# ESP32-C6 register map
Vendor: ESPRESSIF SYSTEMS (SHANGHAI) CO., LTD.; Series: ESP32 C-Series; File version: 12
CPU: RV32IMAC r0p0, little endian, no MPU, no FPU, 0 interrupt priority bits
Address unit: 32 bits
Registers are 32-bit, read-write, reset 0x0 unless marked. A register's access mark holds for its fields unless they carry their own. Offsets are from the block's base; [hi:lo] are bit positions; {n}, {i} and the like mark numbered series.

## LP_TEE — Low-power Trusted Execution Environment
Base 0x600B3400
{0x0+4i} M{i}_MODE_CTRL (i=0..0) reset 0x3 — Tee mode control register
  [1:0] MODE — M0 security level mode: 2'd3: ree_mode2. 2'd2: ree_mode1. 2'd1: ree_mode0. 2'd0: tee_mode
    0=Tee (Tee mode); 1=Ree0 mode; 2=Ree1 mode; 3=Ree2 mode
0x04 CLOCK_GATE reset 0x1 — Clock gating register
  [0] CLK_EN — reg_clk_en
0x90 FORCE_ACC_HP — need_des
  [0] LP_AON_FORCE_ACC_HPMEM_EN
0xFC DATE — Version register

## LP_TIMER — Low-power Timer
Base 0x600B0C00
0x00 TAR0_LOW — need_des
  [31:0] MAIN_TIMER_TAR_LOW0
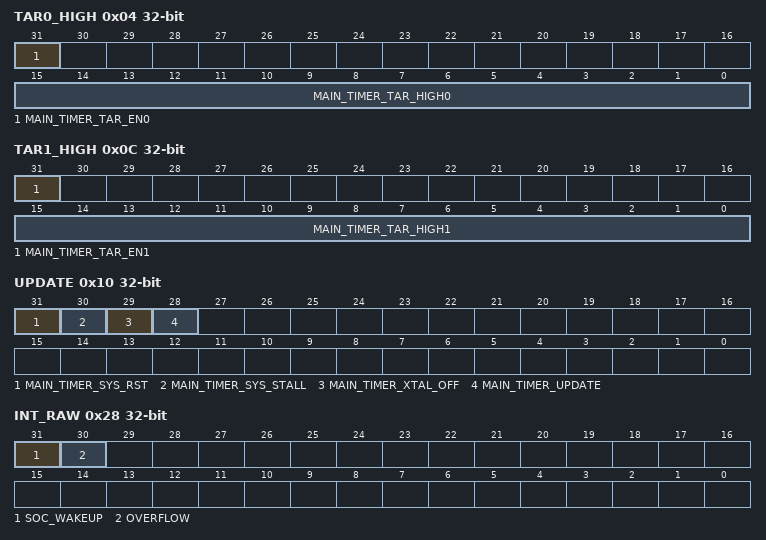
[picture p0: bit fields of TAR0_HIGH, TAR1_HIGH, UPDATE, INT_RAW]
0x04 TAR0_HIGH access per field — need_des
  [31] MAIN_TIMER_TAR_EN0 wo — need_des
  [15:0] MAIN_TIMER_TAR_HIGH0 rw — need_des
0x08 TAR1_LOW — need_des
  [31:0] MAIN_TIMER_TAR_LOW1
0x0C TAR1_HIGH access per field — need_des
  [31] MAIN_TIMER_TAR_EN1 wo — need_des
  [15:0] MAIN_TIMER_TAR_HIGH1 rw — need_des
0x10 UPDATE access per field — need_des
  [31] MAIN_TIMER_SYS_RST rw — need_des
  [30] MAIN_TIMER_SYS_STALL rw — need_des
  [29] MAIN_TIMER_XTAL_OFF rw — need_des
  [28] MAIN_TIMER_UPDATE wo — need_des
0x14 MAIN_BUF0_LOW ro — need_des
  [31:0] MAIN_TIMER_BUF0_LOW
0x18 MAIN_BUF0_HIGH ro — need_des
  [15:0] MAIN_TIMER_BUF0_HIGH
0x1C MAIN_BUF1_LOW ro — need_des
  [31:0] MAIN_TIMER_BUF1_LOW
0x20 MAIN_BUF1_HIGH ro — need_des
  [15:0] MAIN_TIMER_BUF1_HIGH
0x24 MAIN_OVERFLOW wo — need_des
  [31] MAIN_TIMER_ALARM_LOAD
0x28 INT_RAW — need_des
  [31] SOC_WAKEUP — need_des
  [30] OVERFLOW — need_des
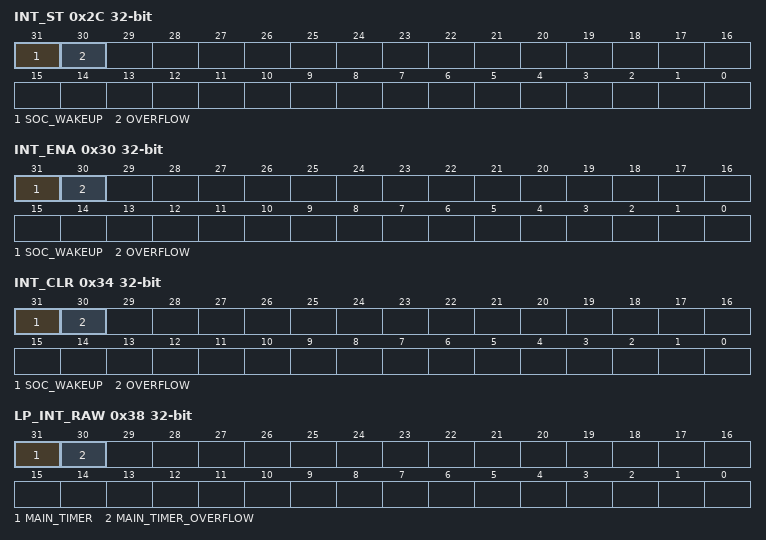
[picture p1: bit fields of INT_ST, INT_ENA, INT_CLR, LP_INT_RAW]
0x2C INT_ST ro — need_des
  [31] SOC_WAKEUP — need_des
  [30] OVERFLOW — need_des
0x30 INT_ENA — need_des
  [31] SOC_WAKEUP — need_des
  [30] OVERFLOW — need_des
0x34 INT_CLR wo — need_des
  [31] SOC_WAKEUP write-1-clears — need_des
  [30] OVERFLOW write-1-clears — need_des
0x38 LP_INT_RAW — need_des
  [31] MAIN_TIMER — need_des
  [30] MAIN_TIMER_OVERFLOW — need_des
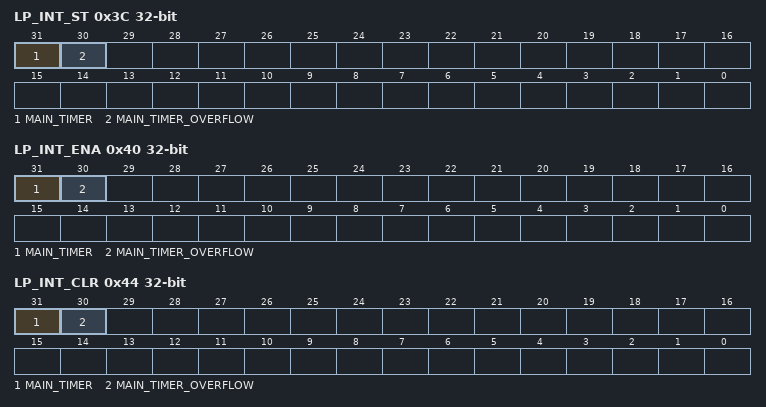
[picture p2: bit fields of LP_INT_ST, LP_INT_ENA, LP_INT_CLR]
0x3C LP_INT_ST ro — need_des
  [31] MAIN_TIMER — need_des
  [30] MAIN_TIMER_OVERFLOW — need_des
0x40 LP_INT_ENA — need_des
  [31] MAIN_TIMER — need_des
  [30] MAIN_TIMER_OVERFLOW — need_des
0x44 LP_INT_CLR wo — need_des
  [31] MAIN_TIMER write-1-clears — need_des
  [30] MAIN_TIMER_OVERFLOW write-1-clears — need_des
0x3FC DATE — need_des

## LP_WDT — Low-power Watchdog Timer
Base 0x600B1C00
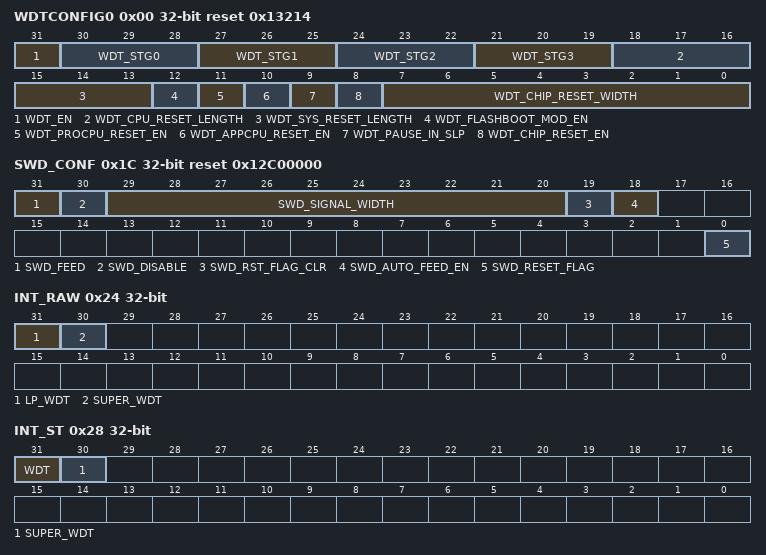
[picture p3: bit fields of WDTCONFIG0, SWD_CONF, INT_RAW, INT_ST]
0x00 WDTCONFIG0 reset 0x13214 — need_des
  [31] WDT_EN — need_des
  [30-3n:28-3n] WDT_STG{n} (n=0..3) — need_des
  [18:16] WDT_CPU_RESET_LENGTH — need_des
  [15:13] WDT_SYS_RESET_LENGTH — need_des
  [12] WDT_FLASHBOOT_MOD_EN — need_des
  [11] WDT_PROCPU_RESET_EN — need_des
  [10] WDT_APPCPU_RESET_EN — need_des
  [9] WDT_PAUSE_IN_SLP — need_des
  [8] WDT_CHIP_RESET_EN — need_des
  [7:0] WDT_CHIP_RESET_WIDTH — need_des
{0x0+4i} WDTCONFIG{i} (i=1..4) reset 0x30D40 — need_des
  [31:0] HOLD
0x14 WDTFEED wo — need_des
  [31] WDT_FEED
0x18 WDTWPROTECT — need_des
  [31:0] WDT_WKEY
0x1C SWD_CONF access per field reset 0x12C00000 — need_des
  [31] SWD_FEED wo — need_des
  [30] SWD_DISABLE rw — need_des
  [29:20] SWD_SIGNAL_WIDTH rw — need_des
  [19] SWD_RST_FLAG_CLR wo — need_des
  [18] SWD_AUTO_FEED_EN rw — need_des
  [0] SWD_RESET_FLAG ro — need_des
0x20 SWD_WPROTECT — need_des
  [31:0] SWD_WKEY
0x24 INT_RAW — need_des
  [31] LP_WDT — need_des
  [30] SUPER_WDT — need_des
0x28 INT_ST ro — need_des
  [31] WDT — need_des
  [30] SUPER_WDT — need_des
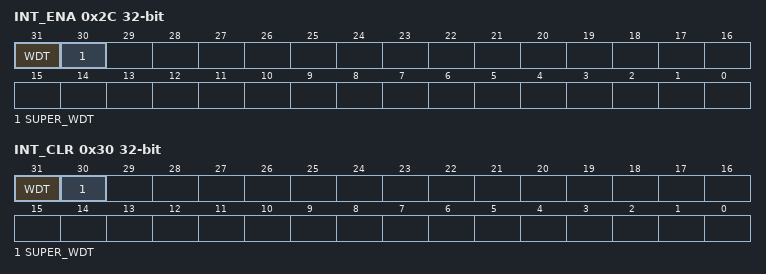
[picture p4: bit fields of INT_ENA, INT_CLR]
0x2C INT_ENA — need_des
  [31] WDT — need_des
  [30] SUPER_WDT — need_des
0x30 INT_CLR wo — need_des
  [31] WDT write-1-clears — need_des
  [30] SUPER_WDT write-1-clears — need_des
0x3FC DATE — need_des

## MEM_MONITOR — MEM_MONITOR Peripheral
Base 0x60092000
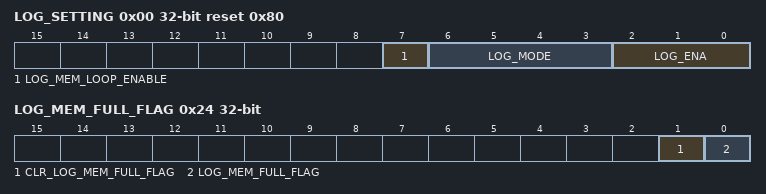
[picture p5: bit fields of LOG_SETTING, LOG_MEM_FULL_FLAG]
0x00 LOG_SETTING reset 0x80 — log config regsiter
  [7] LOG_MEM_LOOP_ENABLE — Set 1 enable mem_loop, it will loop write at the range of MEM_START and MEM_END
  [6:3] LOG_MODE — This field must be onehot. 4'b0001 : WR monitor, 4'b0010: WORD monitor, 4'b0100: HALFWORD monitor, 4'b1000: BYTE monitor.
  [2:0] LOG_ENA — enable bus log. BIT0: hp-cpu, BIT1: lp-cpu, BIT2: DMA.
0x04 LOG_CHECK_DATA — check data regsiter
  [31:0] LOG_CHECK_DATA — The special check data, when write this special data, it will trigger logging.
0x08 LOG_DATA_MASK — check data mask register
  [3:0] LOG_DATA_MASK — byte mask enable, BIT0 mask the first byte of MEM_MONITOR_LOG_CHECK_DATA, and BIT1 mask second byte, and so on.
0x0C LOG_MIN — log boundary regsiter
  [31:0] LOG_MIN — the min address of log range
0x10 LOG_MAX — log boundary regsiter
  [31:0] LOG_MAX — the max address of log range
0x14 LOG_MEM_START — log message store range register
  [31:0] LOG_MEM_START — the start address of writing logging message
0x18 LOG_MEM_END — log message store range register
  [31:0] LOG_MEM_END — the end address of writing logging message
0x1C LOG_MEM_CURRENT_ADDR ro — current writing address.
  [31:0] LOG_MEM_CURRENT_ADDR — means next writing address
0x20 LOG_MEM_ADDR_UPDATE wo — writing address update
  [0] LOG_MEM_ADDR_UPDATE — Set 1 to updata MEM_MONITOR_LOG_MEM_CURRENT_ADDR, when set 1, MEM_MONITOR_LOG_MEM_CURRENT_ADDR will update to MEM_MONITOR_LOG_MEM_START
0x24 LOG_MEM_FULL_FLAG access per field — full flag status register
  [1] CLR_LOG_MEM_FULL_FLAG wo — Set 1 to clr MEM_MONITOR_LOG_MEM_FULL_FLAG
  [0] LOG_MEM_FULL_FLAG ro — 1 means memory write loop at least one time at the range of MEM_START and MEM_END
0x28 CLOCK_GATE — clock gate force on register
  [0] CLK_EN — Set 1 to force on the clk of mem_monitor register
0x3FC DATE — version register
